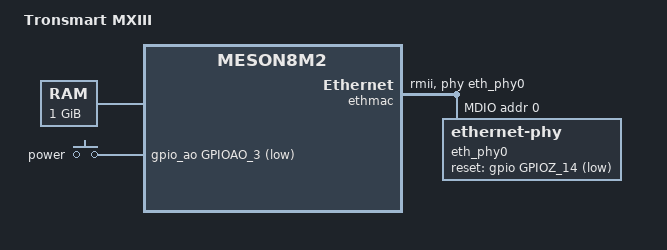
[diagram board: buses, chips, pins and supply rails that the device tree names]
// SPDX-License-Identifier: (GPL-2.0+ OR MIT)
/*
 * Copyright (c) 2018 Martin Blumenstingl <martin.blumenstingl@googlemail.com>
 */

/dts-v1/;

#include "meson8m2-mxiii.dtsi"

/ {
	model = "Tronsmart MXIII";
	compatible = "tronsmart,mxiii", "amlogic,meson8m2";

	memory {
		reg = <0x40000000 0x40000000>;
		device_type = "memory";
	};

	gpio-keys-polled {
		compatible = "gpio-keys-polled";
		poll-interval = <100>;

		button-power {
			label = "power";
			linux,code = <KEY_POWER>;
			gpios = <&gpio_ao GPIOAO_3 GPIO_ACTIVE_LOW>;
		};
	};
};

&ethmac {
	status = "okay";

	pinctrl-0 = <&eth_pins>;
	pinctrl-names = "default";

	phy-handle = <&eth_phy0>;
	phy-mode = "rmii";

	mdio {
		compatible = "snps,dwmac-mdio";
		#address-cells = <1>;
		#size-cells = <0>;

		eth_phy0: ethernet-phy@0 {
			/* IC Plus IP101A/G (0x02430c54) */
			reg = <0>;
			icplus,select-interrupt;
			interrupt-parent = <&gpio_intc>;
			/* GPIODV_29 = 94 and GPIOZ_4 are not working */
			/* interrupts = <94 IRQ_TYPE_LEVEL_LOW>; */

			reset-assert-us = <10000>;
			reset-deassert-us = <10000>;
			reset-gpios = <&gpio GPIOZ_14 GPIO_ACTIVE_LOW>;
		};
	};
};
